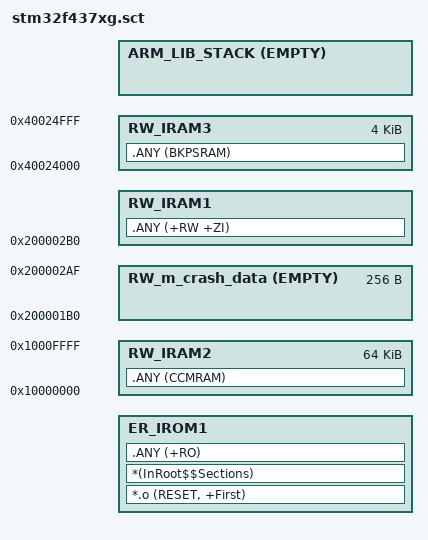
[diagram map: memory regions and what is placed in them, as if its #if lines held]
#! armclang -E --target=arm-arm-none-eabi -x c -mcpu=cortex-m4
; Scatter-Loading Description File
;
; SPDX-License-Identifier: BSD-3-Clause
;******************************************************************************
;* @attention
;*
;* Copyright (c) 2016-2020 STMicroelectronics.
;* All rights reserved.
;*
;* This software component is licensed by ST under BSD 3-Clause license,
;* the "License"; You may not use this file except in compliance with the
;* License. You may obtain a copy of the License at:
;*                        opensource.org/licenses/BSD-3-Clause
;*
;******************************************************************************

#include "../cmsis_nvic.h"

#if !defined(MBED_APP_START)
  #define MBED_APP_START  MBED_ROM_START
#endif

#if !defined(MBED_APP_SIZE)
  #define MBED_APP_SIZE  MBED_ROM_SIZE
#endif

#if !defined(MBED_CONF_TARGET_BOOT_STACK_SIZE)
/* This value is normally defined by the tools to 0x1000 for bare metal and 0x400 for RTOS */
#if defined(MBED_BOOT_STACK_SIZE)
#define MBED_CONF_TARGET_BOOT_STACK_SIZE MBED_BOOT_STACK_SIZE
#else
#define MBED_CONF_TARGET_BOOT_STACK_SIZE 0x400
#endif
#endif

#define Stack_Size MBED_CONF_TARGET_BOOT_STACK_SIZE

#define MBED_RAM_START              0x20000000
#define MBED_RAM_SIZE               0x30000
#define MBED_VECTTABLE_RAM_START    (MBED_RAM_START)
#define MBED_VECTTABLE_RAM_SIZE     0x1B0
#define MBED_CRASH_REPORT_RAM_START (MBED_VECTTABLE_RAM_START + MBED_VECTTABLE_RAM_SIZE)
#define MBED_CRASH_REPORT_RAM_SIZE  0x100
#define MBED_RAM0_START             (MBED_CRASH_REPORT_RAM_START + MBED_CRASH_REPORT_RAM_SIZE)
#define MBED_RAM0_SIZE              (MBED_RAM_SIZE - MBED_VECTTABLE_RAM_SIZE - MBED_CRASH_REPORT_RAM_SIZE)

LR_IROM1 MBED_APP_START MBED_APP_SIZE  {    ; load region size_region

  ER_IROM1 MBED_APP_START MBED_APP_SIZE  {  ; load address = execution address
   *.o (RESET, +First)
   *(InRoot$$Sections)
   .ANY (+RO)
  }

  ; Total: 107 vectors = 428 bytes (0x1AC) 8-byte aligned = 0x1B0 (0x1AC + 0x4) to be reserved in RAM
  RW_IRAM1 (MBED_RAM0_START) (MBED_RAM0_SIZE-Stack_Size)  {  ; RW data
   .ANY (+RW +ZI)
  }
  
  RW_IRAM2 (0x10000000) (0x10000)  {  ; RW data
   .ANY (CCMRAM)
  }
  
  RW_m_crash_data MBED_CRASH_REPORT_RAM_START EMPTY MBED_CRASH_REPORT_RAM_SIZE { ; RW data
  }
  
  RW_IRAM3 0x40024000 4096  {  ; 4 kbytes of Backup SRAM
   .ANY (BKPSRAM)
  }

  ARM_LIB_STACK (MBED_RAM0_START+MBED_RAM0_SIZE) EMPTY -Stack_Size { ; stack
  }
}
